AUTOSAR XML (schema 4-3-0)
package /ComponentTypes
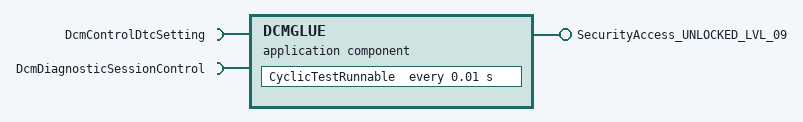
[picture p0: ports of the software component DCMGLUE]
  application sw component type DCMGLUE
    provide port SecurityAccess_UNLOCKED_LVL_09: provided-com-specs=[{operation=CompareKey, queue-length=1}, {operation=GetSeed, queue-length=1}], provided-interface=SecurityAccess_UNLOCKED_LVL_09
    require port DcmControlDtcSetting: mode-switch-receiver-com-spec{enhanced-mode-api=false, supports-asynchronous-mode-switch=false}, required-interface=DcmControlDtcSetting
    require port DcmDiagnosticSessionControl: mode-switch-receiver-com-spec{enhanced-mode-api=false, supports-asynchronous-mode-switch=false}, required-interface=DcmDiagnosticSessionControl
    behavior DCMGLUE_InternalBehavior
      timing event TMT_CyclicTestRunnable: start-on-event=CyclicTestRunnable, period=0.01
      swc mode switch event MST_DcmDtcControlRunnable_0: start-on-event=DcmDtcControlRunnable, activation=ON-ENTRY, mode=DcmControlDtcSetting.DcmControlDtcSetting.DISABLEDTCSETTING
      swc mode switch event MST_DcmDtcControlRunnable_1: start-on-event=DcmDtcControlRunnable, activation=ON-ENTRY, mode=DcmControlDtcSetting.DcmControlDtcSetting.ENABLEDTCSETTING
      swc mode switch event MST_DcmSessionControlRunnable_0: start-on-event=DcmSessionControlRunnable, activation=ON-TRANSITION
        mode:
          DcmDiagnosticSessionControl.DcmDiagnosticSessionControl.ProgrammingSession
          DcmDiagnosticSessionControl.DcmDiagnosticSessionControl.DefaultSession
      operation invoked event OIT_ProgDcmCompareKeyRunnable_SecurityAccess_UNLOCKED_LVL_09_CompareKey: start-on-event=ProgDcmCompareKeyRunnable, operation=SecurityAccess_UNLOCKED_LVL_09.CompareKey
      operation invoked event OIT_ProgDcmGetSeedRunnable_SecurityAccess_UNLOCKED_LVL_09_GetSeed: start-on-event=ProgDcmGetSeedRunnable, operation=SecurityAccess_UNLOCKED_LVL_09.GetSeed
      5 x runnable:
        CyclicTestRunnable
        DcmDtcControlRunnable: mode-access-point=DcmControlDtcSetting.DcmControlDtcSetting
        DcmSessionControlRunnable: mode-access-point=DcmDiagnosticSessionControl.DcmDiagnosticSessionControl
        ProgDcmCompareKeyRunnable
        ProgDcmGetSeedRunnable
  swc implementation DCMGLUE_Implementation: behavior=DCMGLUE_InternalBehavior
    code-descriptors:
      code Default: artifact-descriptors=autosar-engineering-object={short-label=Default, category=SWSRC}
